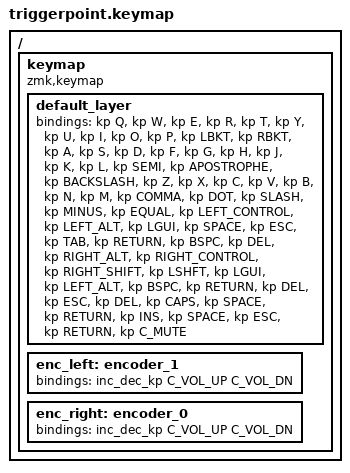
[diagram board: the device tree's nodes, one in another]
/*
 * Copyright (c) 2022 The ZMK Contributors
 *
 * SPDX-License-Identifier: MIT
 */

#include <behaviors.dtsi>
#include <dt-bindings/zmk/keys.h>
#include <dt-bindings/zmk/bt.h>

/ {
  keymap {
    compatible = "zmk,keymap";

    default_layer {
      bindings = <
        &kp Q  &kp W  &kp E  &kp R  &kp T  &kp Y  &kp U  &kp I  &kp O  &kp P  &kp LBKT  &kp RBKT
        &kp A  &kp S  &kp D  &kp F  &kp G  &kp H  &kp J  &kp K  &kp L  &kp SEMI &kp APOSTROPHE &kp BACKSLASH
        &kp Z  &kp X  &kp C  &kp V  &kp B  &kp N  &kp M  &kp COMMA &kp DOT &kp SLASH &kp MINUS &kp EQUAL

        &kp LEFT_CONTROL &kp LEFT_ALT &kp LGUI &kp SPACE
        &kp ESC   &kp TAB  &kp RETURN  &kp BSPC &kp DEL
        &kp RIGHT_ALT  &kp RIGHT_CONTROL &kp RIGHT_SHIFT

        &kp LSHFT &kp LGUI &kp LEFT_ALT &kp BSPC &kp RETURN  &kp DEL  &kp ESC &kp DEL &kp CAPS &kp SPACE &kp RETURN &kp INS

        &kp SPACE
        &kp ESC
        &kp RETURN
        &kp C_MUTE
      >;
    };

    enc_left:  encoder_1 { bindings = <&inc_dec_kp C_VOL_UP C_VOL_DN>; };
    enc_right: encoder_0 { bindings = <&inc_dec_kp C_VOL_UP C_VOL_DN>; };
  };
};
